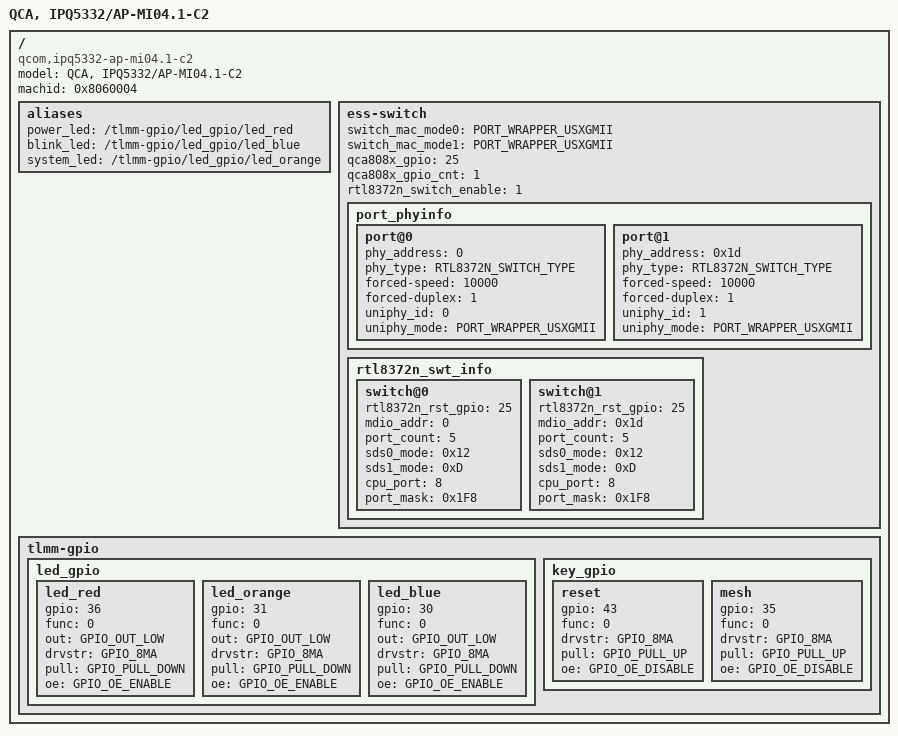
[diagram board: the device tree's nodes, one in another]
/*
 * Copyright (c) 2016-2019, The Linux Foundation. All rights reserved.
 *
 * Copyright (c) 2022-2023 Qualcomm Innovation Center, Inc. All rights reserved.
 *
 * This program is free software; you can redistribute it and/or modify
 * it under the terms of the GNU General Public License version 2 and
 * only version 2 as published by the Free Software Foundation.
 *
 * This program is distributed in the hope that it will be useful,
 * but WITHOUT ANY WARRANTY; without even the implied warranty of
 * MERCHANTABILITY or FITNESS FOR A PARTICULAR PURPOSE.  See the
 * GNU General Public License for more details.
 */

/dts-v1/;
#include "ipq5332-mi04.1.dts"
/ {
	model = "QCA, IPQ5332/AP-MI04.1-C2";
	machid = <0x8060004>;
	compatible = "qcom,ipq5332-ap-mi04.1-c2", "qcom,ipq5332";

	aliases {
        /delete-property/ mmc;
		power_led = "/tlmm-gpio/led_gpio/led_red";
		blink_led = "/tlmm-gpio/led_gpio/led_blue";
		system_led = "/tlmm-gpio/led_gpio/led_orange";
	};

	ess-switch {
		/delete-property/ napa_gpio;
		/delete-property/ napa_gpio_cnt;
		/delete-property/ qca8084_switch_enable;

		switch_mac_mode0 = <PORT_WRAPPER_USXGMII>;
		switch_mac_mode1 = <PORT_WRAPPER_USXGMII>;
		qca808x_gpio = <25>;
		qca808x_gpio_cnt = <1>;
		rtl8372n_switch_enable = <1>;

		port_phyinfo {
			port@0 {
				phy_address = <0>;
				phy_type = <RTL8372N_SWITCH_TYPE>;
				forced-speed = <10000>;
				forced-duplex = <1>;
				uniphy_id = <0>;
				uniphy_mode = <PORT_WRAPPER_USXGMII>;
			};
			port@1 {
				phy_address = <0x1d>;
				phy_type = <RTL8372N_SWITCH_TYPE>;
				forced-speed = <10000>;
				forced-duplex = <1>;
				uniphy_id = <1>;
				uniphy_mode = <PORT_WRAPPER_USXGMII>;
			};
		};

		/delete-node/ qca8084_swt_info;

		rtl8372n_swt_info {
			switch@0 {
				rtl8372n_rst_gpio = <25>;
				mdio_addr = <0>;
				port_count = <5>;
				sds0_mode = <0x12>;
				sds1_mode = <0xD>;
				cpu_port = <8>;
				port_mask = <0x1F8>;
			};
			switch@1 {
				rtl8372n_rst_gpio = <25>;
				mdio_addr = <0x1d>;
				port_count = <5>;
				sds0_mode = <0x12>;
				sds1_mode = <0xD>;
				cpu_port = <8>;
				port_mask = <0x1F8>;
			};
		};
	};

	tlmm-gpio {
		led_gpio {
			led_red {
				gpio = <36>;
				func = <0>;
				out = <GPIO_OUT_LOW>;
				drvstr = <GPIO_8MA>;
				pull = <GPIO_PULL_DOWN>;
				oe = <GPIO_OE_ENABLE>;
			};
			led_orange {
				gpio = <31>;
				func = <0>;
				out = <GPIO_OUT_LOW>;
				drvstr = <GPIO_8MA>;
				pull = <GPIO_PULL_DOWN>;
				oe = <GPIO_OE_ENABLE>;
			};
			led_blue {
				gpio = <30>;
				func = <0>;
				out = <GPIO_OUT_LOW>;
				drvstr = <GPIO_8MA>;
				pull = <GPIO_PULL_DOWN>;
				oe = <GPIO_OE_ENABLE>;
			};
		};
		key_gpio {
			reset {
				gpio = <43>;
				func = <0>;
				drvstr = <GPIO_8MA>;
				pull = <GPIO_PULL_UP>;
				oe = <GPIO_OE_DISABLE>;
			};
			mesh {
				gpio = <35>;
				func = <0>;
				drvstr = <GPIO_8MA>;
				pull = <GPIO_PULL_UP>;
				oe = <GPIO_OE_DISABLE>;
			};
		};
	};
};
